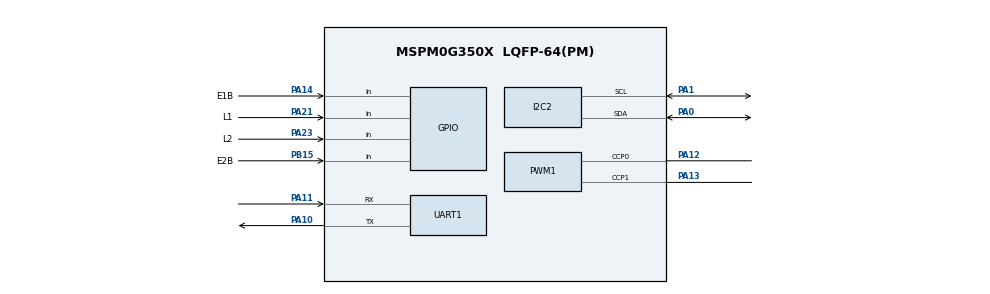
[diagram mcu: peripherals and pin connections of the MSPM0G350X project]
/**
 * @cliArgs --device "MSPM0G350X" --part "Default" --package "LQFP-64(PM)" --product "mspm0_sdk@2.11.00.07"
 * @versions {"tool":"1.26.2+4477"}
 */

/**
 * Import the modules used in this configuration.
 */
const GPIO    = scripting.addModule("/ti/driverlib/GPIO", {}, false);
const GPIO1   = GPIO.addInstance();
const GPIO2   = GPIO.addInstance();
const GPIO3   = GPIO.addInstance();
const GPIO4   = GPIO.addInstance();
const I2C     = scripting.addModule("/ti/driverlib/I2C", {}, false);
const I2C1    = I2C.addInstance();
const I2C2    = I2C.addInstance();
const PWM     = scripting.addModule("/ti/driverlib/PWM", {}, false);
const PWM1    = PWM.addInstance();
const SYSCTL  = scripting.addModule("/ti/driverlib/SYSCTL");
const SYSTICK = scripting.addModule("/ti/driverlib/SYSTICK");
const TIMER   = scripting.addModule("/ti/driverlib/TIMER", {}, false);
const TIMER1  = TIMER.addInstance();
const UART    = scripting.addModule("/ti/driverlib/UART", {}, false);
const UART1   = UART.addInstance();

/**
 * Write custom configuration values to the imported modules.
 */
const divider9       = system.clockTree["UDIV"];
divider9.divideValue = 2;

const multiplier2         = system.clockTree["PLL_QDIV"];
multiplier2.multiplyValue = 4;

const mux4       = system.clockTree["EXHFMUX"];
mux4.inputSelect = "EXHFMUX_XTAL";

const mux8       = system.clockTree["HSCLKMUX"];
mux8.inputSelect = "HSCLKMUX_SYSPLL0";

const mux12       = system.clockTree["SYSPLLMUX"];
mux12.inputSelect = "zSYSPLLMUX_HFCLK";

const pinFunction4     = system.clockTree["HFXT"];
pinFunction4.inputFreq = 40;
pinFunction4.enable    = true;

GPIO1.$name                         = "LED";
GPIO1.port                          = "PORTB";
GPIO1.associatedPins[0].$name       = "PIN_22";
GPIO1.associatedPins[0].assignedPin = "22";

const Board = scripting.addModule("/ti/driverlib/Board", {}, false);

GPIO2.$name                              = "KEY";
GPIO2.port                               = "PORTB";
GPIO2.associatedPins[0].$name            = "KEY0";
GPIO2.associatedPins[0].direction        = "INPUT";
GPIO2.associatedPins[0].assignedPin      = "21";
GPIO2.associatedPins[0].interruptEn      = true;
GPIO2.associatedPins[0].internalResistor = "PULL_UP";
GPIO2.associatedPins[0].polarity         = "FALL";

GPIO3.$name                              = "MOTOR";
GPIO3.associatedPins.create(8);
GPIO3.associatedPins[0].$name            = "A1N1";
GPIO3.associatedPins[0].assignedPort     = "PORTA";
GPIO3.associatedPins[0].assignedPin      = "16";
GPIO3.associatedPins[1].$name            = "A1N2";
GPIO3.associatedPins[1].assignedPort     = "PORTA";
GPIO3.associatedPins[1].assignedPin      = "17";
GPIO3.associatedPins[2].$name            = "E1A";
GPIO3.associatedPins[2].direction        = "INPUT";
GPIO3.associatedPins[2].interruptEn      = true;
GPIO3.associatedPins[2].polarity         = "RISE";
GPIO3.associatedPins[2].internalResistor = "PULL_DOWN";
GPIO3.associatedPins[2].assignedPort     = "PORTA";
GPIO3.associatedPins[2].assignedPin      = "15";
GPIO3.associatedPins[3].direction        = "INPUT";
GPIO3.associatedPins[3].internalResistor = "PULL_DOWN";
GPIO3.associatedPins[3].$name            = "E1B";
GPIO3.associatedPins[3].pin.$assign      = "PA14";
GPIO3.associatedPins[4].$name            = "B1N1";
GPIO3.associatedPins[4].assignedPort     = "PORTA";
GPIO3.associatedPins[4].assignedPin      = "24";
GPIO3.associatedPins[5].$name            = "B1N2";
GPIO3.associatedPins[5].assignedPort     = "PORTA";
GPIO3.associatedPins[5].assignedPin      = "22";
GPIO3.associatedPins[6].$name            = "E2A";
GPIO3.associatedPins[6].direction        = "INPUT";
GPIO3.associatedPins[6].interruptEn      = true;
GPIO3.associatedPins[6].polarity         = "RISE";
GPIO3.associatedPins[6].internalResistor = "PULL_DOWN";
GPIO3.associatedPins[7].$name            = "E2B";
GPIO3.associatedPins[7].subChanID        = 1;
GPIO3.associatedPins[7].direction        = "INPUT";
GPIO3.associatedPins[7].internalResistor = "PULL_DOWN";
GPIO3.associatedPins[7].pin.$assign      = "PB15";

GPIO4.$name                         = "HUIDU";
GPIO4.associatedPins.create(5);
GPIO4.associatedPins[0].$name       = "L2";
GPIO4.associatedPins[0].direction   = "INPUT";
GPIO4.associatedPins[0].pin.$assign = "PA23";
GPIO4.associatedPins[1].$name       = "L1";
GPIO4.associatedPins[1].direction   = "INPUT";
GPIO4.associatedPins[1].pin.$assign = "PA21";
GPIO4.associatedPins[2].$name       = "M";
GPIO4.associatedPins[2].direction   = "INPUT";
GPIO4.associatedPins[3].$name       = "R1";
GPIO4.associatedPins[3].direction   = "INPUT";
GPIO4.associatedPins[4].$name       = "R2";
GPIO4.associatedPins[4].direction   = "INPUT";

I2C1.$name                             = "OLED";
I2C1.basicEnableController             = true;
I2C1.basicControllerStandardBusSpeed   = "Fast";
I2C1.peripheral.$assign                = "I2C1";
I2C1.sdaPinConfig.$name                = "ti_driverlib_gpio_GPIOPinGeneric0";
I2C1.sdaPinConfig.hideOutputInversion  = scripting.forceWrite(false);
I2C1.sdaPinConfig.onlyInternalResistor = scripting.forceWrite(false);
I2C1.sdaPinConfig.passedPeripheralType = scripting.forceWrite("Digital");
I2C1.sdaPinConfig.enableConfig         = true;
I2C1.sdaPinConfig.internalResistor     = "PULL_UP";
I2C1.sclPinConfig.$name                = "ti_driverlib_gpio_GPIOPinGeneric1";
I2C1.sclPinConfig.hideOutputInversion  = scripting.forceWrite(false);
I2C1.sclPinConfig.onlyInternalResistor = scripting.forceWrite(false);
I2C1.sclPinConfig.passedPeripheralType = scripting.forceWrite("Digital");
I2C1.sclPinConfig.enableConfig         = true;
I2C1.sclPinConfig.internalResistor     = "PULL_UP";

I2C2.$name                             = "MPU6050";
I2C2.basicEnableController             = true;
I2C2.advDigitalGlitchFilter            = "CLOCKS_1";
I2C2.advControllerRXFIFOTRIG           = "BYTES_8";
I2C2.advControllerTXFIFOTRIG           = "BYTES_7";
I2C2.enableDMAEvent1                   = false;
I2C2.enableDMAEvent2                   = false;
I2C2.basicControllerStandardBusSpeed   = "Standard";
I2C2.peripheral.sdaPin.$assign         = "PA0";
I2C2.peripheral.sclPin.$assign         = "PA1";
I2C2.sdaPinConfig.$name                = "ti_driverlib_gpio_GPIOPinGeneric6";
I2C2.sdaPinConfig.hideOutputInversion  = scripting.forceWrite(false);
I2C2.sdaPinConfig.onlyInternalResistor = scripting.forceWrite(false);
I2C2.sdaPinConfig.passedPeripheralType = scripting.forceWrite("Digital");
I2C2.sclPinConfig.$name                = "ti_driverlib_gpio_GPIOPinGeneric7";
I2C2.sclPinConfig.hideOutputInversion  = scripting.forceWrite(false);
I2C2.sclPinConfig.onlyInternalResistor = scripting.forceWrite(false);
I2C2.sclPinConfig.passedPeripheralType = scripting.forceWrite("Digital");

PWM1.timerStartTimer                    = true;
PWM1.timerCount                         = 4000;
PWM1.pwmMode                            = "EDGE_ALIGN_UP";
PWM1.$name                              = "PWMA";
PWM1.peripheral.$assign                 = "TIMG0";
PWM1.peripheral.ccp0Pin.$assign         = "PA12";
PWM1.peripheral.ccp1Pin.$assign         = "PA13";
PWM1.PWM_CHANNEL_0.$name                = "ti_driverlib_pwm_PWMTimerCC0";
PWM1.PWM_CHANNEL_1.$name                = "ti_driverlib_pwm_PWMTimerCC1";
PWM1.ccp0PinConfig.direction            = scripting.forceWrite("OUTPUT");
PWM1.ccp0PinConfig.hideOutputInversion  = scripting.forceWrite(false);
PWM1.ccp0PinConfig.onlyInternalResistor = scripting.forceWrite(false);
PWM1.ccp0PinConfig.passedPeripheralType = scripting.forceWrite("Digital");
PWM1.ccp0PinConfig.$name                = "ti_driverlib_gpio_GPIOPinGeneric4";
PWM1.ccp1PinConfig.direction            = scripting.forceWrite("OUTPUT");
PWM1.ccp1PinConfig.hideOutputInversion  = scripting.forceWrite(false);
PWM1.ccp1PinConfig.onlyInternalResistor = scripting.forceWrite(false);
PWM1.ccp1PinConfig.passedPeripheralType = scripting.forceWrite("Digital");
PWM1.ccp1PinConfig.$name                = "ti_driverlib_gpio_GPIOPinGeneric5";

SYSCTL.forceDefaultClkConfig = true;
SYSCTL.clockTreeEn           = true;

SYSTICK.periodEnable    = true;
SYSTICK.period          = 80000;
SYSTICK.interruptEnable = true;
SYSTICK.systickEnable   = true;

TIMER1.$name              = "TIM_MOTOR";
TIMER1.timerMode          = "PERIODIC_UP";
TIMER1.timerClkPrescale   = 80;
TIMER1.timerPeriod        = "0.01";
TIMER1.timerStartTimer    = true;
TIMER1.interrupts         = ["LOAD"];
TIMER1.peripheral.$assign = "TIMA0";

UART1.$name                            = "PRINT";
UART1.targetBaudRate                   = 115200;
UART1.enabledInterrupts                = ["RX"];
UART1.peripheral.rxPin.$assign         = "PA11";
UART1.peripheral.txPin.$assign         = "PA10";
UART1.txPinConfig.direction            = scripting.forceWrite("OUTPUT");
UART1.txPinConfig.hideOutputInversion  = scripting.forceWrite(false);
UART1.txPinConfig.onlyInternalResistor = scripting.forceWrite(false);
UART1.txPinConfig.passedPeripheralType = scripting.forceWrite("Digital");
UART1.txPinConfig.$name                = "ti_driverlib_gpio_GPIOPinGeneric2";
UART1.txPinConfig.enableConfig         = true;
UART1.rxPinConfig.hideOutputInversion  = scripting.forceWrite(false);
UART1.rxPinConfig.onlyInternalResistor = scripting.forceWrite(false);
UART1.rxPinConfig.passedPeripheralType = scripting.forceWrite("Digital");
UART1.rxPinConfig.$name                = "ti_driverlib_gpio_GPIOPinGeneric3";
UART1.rxPinConfig.enableConfig         = true;

/**
 * Pinmux solution for unlocked pins/peripherals. This ensures that minor changes to the automatic solver in a future
 * version of the tool will not impact the pinmux you originally saw.  These lines can be completely deleted in order to
 * re-solve from scratch.
 */
pinFunction4.peripheral.$suggestSolution           = "SYSCTL";
pinFunction4.peripheral.hfxInPin.$suggestSolution  = "PA5";
pinFunction4.peripheral.hfxOutPin.$suggestSolution = "PA6";
GPIO1.associatedPins[0].pin.$suggestSolution       = "PB22";
Board.peripheral.$suggestSolution                  = "DEBUGSS";
Board.peripheral.swclkPin.$suggestSolution         = "PA20";
Board.peripheral.swdioPin.$suggestSolution         = "PA19";
GPIO2.associatedPins[0].pin.$suggestSolution       = "PB21";
GPIO3.associatedPins[0].pin.$suggestSolution       = "PA16";
GPIO3.associatedPins[1].pin.$suggestSolution       = "PA17";
GPIO3.associatedPins[2].pin.$suggestSolution       = "PA15";
GPIO3.associatedPins[4].pin.$suggestSolution       = "PA24";
GPIO3.associatedPins[5].pin.$suggestSolution       = "PA22";
GPIO3.associatedPins[6].pin.$suggestSolution       = "PB13";
GPIO4.associatedPins[2].pin.$suggestSolution       = "PB14";
GPIO4.associatedPins[3].pin.$suggestSolution       = "PB16";
GPIO4.associatedPins[4].pin.$suggestSolution       = "PB17";
I2C1.peripheral.sdaPin.$suggestSolution            = "PA18";
I2C1.peripheral.sclPin.$suggestSolution            = "PA29";
I2C2.peripheral.$suggestSolution                   = "I2C0";
UART1.peripheral.$suggestSolution                  = "UART0";
